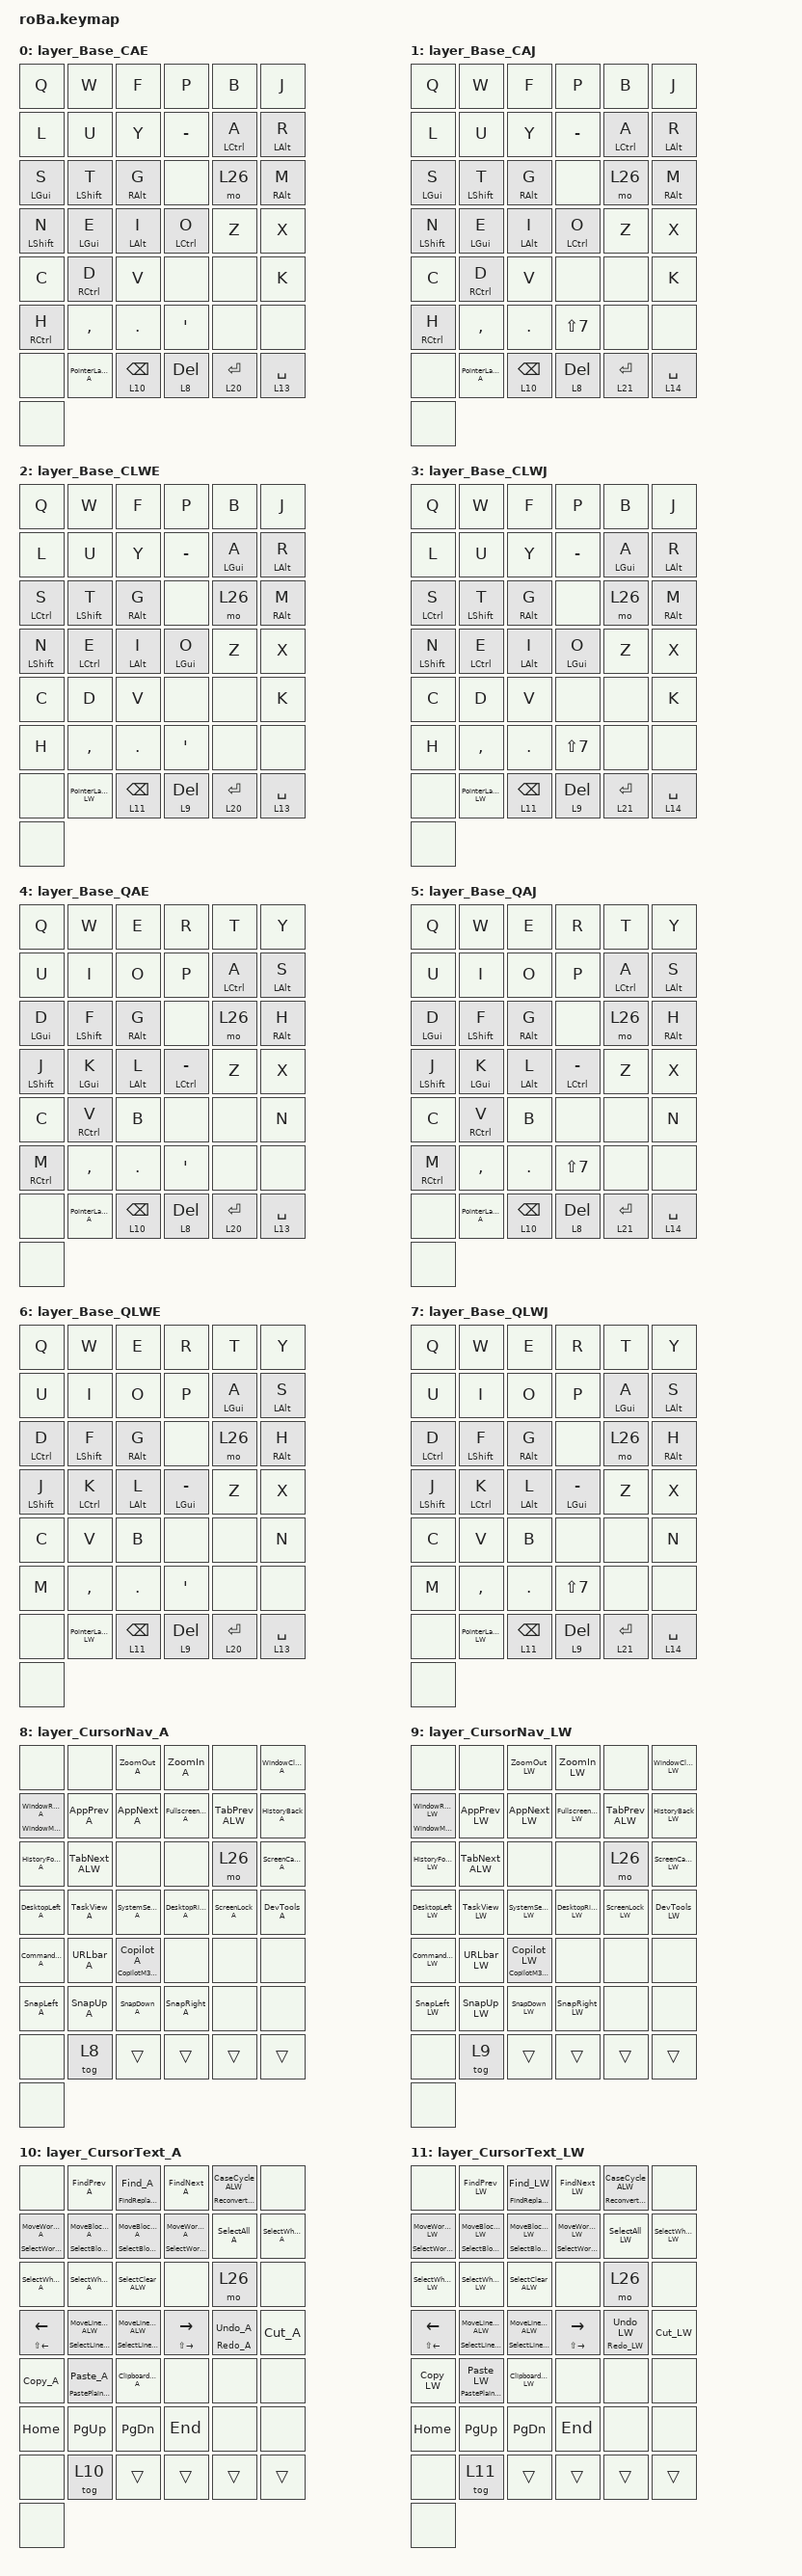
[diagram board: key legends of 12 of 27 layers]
/*
 * Copyright (c) 2020 The ZMK Contributors
 * Copyright (c) 2025 Innaworks Development Limited, trading as MoErgo
 *
 * SPDX-License-Identifier: MIT
 */


/* roBa conversion generated from 9605b8a6-7994-4d04-98d7-80160d29d007_ks35.json; based on last-known-good roBa keymap structure. */

#include <behaviors.dtsi>

/* Include all behavior includes needed */

#include <dt-bindings/zmk/outputs.h>
#include <dt-bindings/zmk/keys.h>
#include <dt-bindings/zmk/bt.h>
#include <dt-bindings/zmk/rgb.h>

#include <input/processors.dtsi>
#include <dt-bindings/zmk/input_transform.h>
#include <zephyr/dt-bindings/input/input-event-codes.h>

/* On demand includes */
#include <dt-bindings/zmk/input_transform.h>
#include <dt-bindings/zmk/pointing.h>
#include <input/processors.dtsi>

/* Helper Macros, based on https://github.com/urob/zmk-helpers/ */

#pragma once

#define ZMK_HELPER_STRINGIFY(x) #x

// Preprocessor mechanism to overload macros, cf. https://stackoverflow.com/a/27051616/6114651
#define VARGS_(_10, _9, _8, _7, _6, _5, _4, _3, _2, _1, N, ...) N
#define VARGS(...) VARGS_(__VA_ARGS__, 10, 9, 8, 7, 6, 5, 4, 3, 2, 1, 0)
#define CONCAT_(a, b) a##b
#define CONCAT(a, b) CONCAT_(a, b)

#define ZMK_BEHAVIOR_CORE_tap_dance  \
    compatible = "zmk,behavior-tap-dance"; \
    #binding-cells = <0>

#define ZMK_BEHAVIOR(name, type, ...) \
    name: name { \
        ZMK_BEHAVIOR_CORE_ ## type; \
        __VA_ARGS__ \
    };

#define ZMK_TAP_DANCE(name, ...) \
    ZMK_BEHAVIOR(name, tap_dance, __VA_ARGS__)

#define ZMK_TD_LAYER(name, layer) \
    ZMK_TAP_DANCE(name, \
        tapping-term-ms = <200>; \
        bindings = <&mo layer>, <&to layer>; \
)


/* Automatically generated roBa layer name defines */
#define LAYER_Base_CAE 0
#define LAYER_Base_CAJ 1
#define LAYER_Base_CLWE 2
#define LAYER_Base_CLWJ 3
#define LAYER_Base_QAE 4
#define LAYER_Base_QAJ 5
#define LAYER_Base_QLWE 6
#define LAYER_Base_QLWJ 7
#define LAYER_CursorNav_A 8
#define LAYER_CursorNav_LW 9
#define LAYER_CursorText_A 10
#define LAYER_CursorText_LW 11
#define LAYER_Magic 12
#define LAYER_Number_E 13
#define LAYER_Number_J 14
#define LAYER_Pointer_Default_A 15
#define LAYER_Pointer_Default_LW 16
#define LAYER_Pointer_Precision 17
#define LAYER_Pointer_Rapid 18
#define LAYER_Pointer_Travel 19
#define LAYER_Symbol_E 20
#define LAYER_Symbol_J 21
#define LAYER_TypingAutoshift_C 22
#define LAYER_TypingAutoshift_Q 23
#define LAYER_TypingFocus_C 24
#define LAYER_TypingFocus_Q 25
#define LAYER_HSCROLL 26

#define COMBO_MAX_COMBOS_PER_KEY 8


/* System behavior and macros */


/ {
    macros {
        rgb_ug_status_macro: rgb_ug_status_macro {
            label = "RGB_UG_STATUS";
            compatible = "zmk,behavior-macro";
            #binding-cells = <0>;
            bindings
                = <&rgb_ug RGB_TOG>;
        };

        SelectAll_A: SelectAll_A {
            label = "&SELECTALL_A";
            compatible = "zmk,behavior-macro";
            #binding-cells = <0>;
            bindings = <&kp LG(A)>;
        };

        SelectAll_LW: SelectAll_LW {
            label = "&SELECTALL_LW";
            compatible = "zmk,behavior-macro";
            #binding-cells = <0>;
            bindings = <&kp LC(A)>;
        };

        IME_Off_A: IME_Off_A {
            label = "&IME_OFF_A";
            compatible = "zmk,behavior-macro";
            #binding-cells = <0>;
            bindings = <&kp LANG2>;
        };

        IME_Off_LW: IME_Off_LW {
            label = "&IME_OFF_LW";
            compatible = "zmk,behavior-macro";
            #binding-cells = <0>;
            bindings = <&kp INT5>;
        };

        IME_ON_A: IME_ON_A {
            label = "&IME_ON_A";
            compatible = "zmk,behavior-macro";
            #binding-cells = <0>;
            bindings = <&kp LANG1>;
        };

        IME_ON_LW: IME_ON_LW {
            label = "&IME_ON_LW";
            compatible = "zmk,behavior-macro";
            #binding-cells = <0>;
            bindings = <&kp INT4>;
        };

    };
};



/ {
    behaviors {
        magic: magic {
            compatible = "zmk,behavior-hold-tap";
            label = "MAGIC_HOLD_TAP";
            #binding-cells = <2>;
            flavor = "tap-preferred";
            tapping-term-ms = <200>;
            bindings = <&mo>, <&rgb_ug_status_macro>;
        };
    };
};


/* Custom Defined Behaviors */


/* Automatically generated macro definitions */
/ {
    macros {

        AppNext_A: AppNext_A {
            label = "&APPNEXT_A";
            compatible = "zmk,behavior-macro";
            #binding-cells = <0>;
            bindings = <&kp LG(TAB)>;
        };

        AppNext_LW: AppNext_LW {
            label = "&APPNEXT_LW";
            compatible = "zmk,behavior-macro";
            #binding-cells = <0>;
            bindings = <&kp LA(TAB)>;
        };

        AppPrev_A: AppPrev_A {
            label = "&APPPREV_A";
            compatible = "zmk,behavior-macro";
            #binding-cells = <0>;
            bindings = <&kp LG(LS(TAB))>;
        };

        AppPrev_LW: AppPrev_LW {
            label = "&APPPREV_LW";
            compatible = "zmk,behavior-macro";
            #binding-cells = <0>;
            bindings = <&kp LA(LS(TAB))>;
        };

        // AutoShift Helper- &AS main macro is chained to &AS_HT hold tap and &AS_Shifted macro - TailorKey
        AS_Shifted_v1_TKZ: AS_Shifted_v1_TKZ {
            label = "&AS_SHIFTED_V1_TKZ";
            compatible = "zmk,behavior-macro-one-param";
            #binding-cells = <1>;
            tap-ms = <0>;
            wait-ms = <0>;
            bindings = <&macro_press>
                , <&kp LSHFT>
                , <&macro_tap>
                , <&macro_param_1to1>
                , <&kp MACRO_PLACEHOLDER>
                , <&macro_release>
                , <&kp LSHFT>;
        };

        // AutoShift (Assign &AS to a Key) - &AS main macro is chained to &AS_HT hold tap and &AS_Shifted macro - TailorKey
        AS_v1_TKZ: AS_v1_TKZ {
            label = "&AS_V1_TKZ";
            compatible = "zmk,behavior-macro-one-param";
            #binding-cells = <1>;
            tap-ms = <0>;
            wait-ms = <0>;
            bindings = <&macro_press>
                , <&macro_param_1to1>
                , <&macro_param_1to2>
                , <&HT_AutoShift MACRO_PLACEHOLDER MACRO_PLACEHOLDER>
                , <&macro_pause_for_release>
                , <&macro_release>
                , <&macro_param_1to1>
                , <&macro_param_1to2>
                , <&HT_AutoShift MACRO_PLACEHOLDER MACRO_PLACEHOLDER>;
        };

        CaseCycle_ALW: CaseCycle_ALW {
            label = "&CASECYCLE_ALW";
            compatible = "zmk,behavior-macro";
            #binding-cells = <0>;
            bindings = <&kp LS(F3)>;
        };

        ClipboardHistory_A: ClipboardHistory_A {
            label = "&CLIPBOARDHISTORY_A";
            compatible = "zmk,behavior-macro";
            #binding-cells = <0>;
            bindings = <&kp LG(SPACE)>
                , <&kp LG(N4)>;
        };

        ClipboardHistory_LW: ClipboardHistory_LW {
            label = "&CLIPBOARDHISTORY_LW";
            compatible = "zmk,behavior-macro";
            #binding-cells = <0>;
            bindings = <&kp LG(V)>;
        };

        CommandPalette_A: CommandPalette_A {
            label = "&COMMANDPALETTE_A";
            compatible = "zmk,behavior-macro";
            #binding-cells = <0>;
            bindings = <&kp LG(LS(P))>;
        };

        CommandPalette_LW: CommandPalette_LW {
            label = "&COMMANDPALETTE_LW";
            compatible = "zmk,behavior-macro";
            #binding-cells = <0>;
            bindings = <&kp LS(LC(P))>;
        };

        Copilot_A: Copilot_A {
            label = "&COPILOT_A";
            compatible = "zmk,behavior-macro";
            #binding-cells = <0>;
            bindings = <&kp LA(SPACE)>;
        };

        Copilot_LW: Copilot_LW {
            label = "&COPILOT_LW";
            compatible = "zmk,behavior-macro";
            #binding-cells = <0>;
            bindings = <&kp LG(C)>;
        };

        CopilotM365_A: CopilotM365_A {
            label = "&COPILOTM365_A";
            compatible = "zmk,behavior-macro";
            #binding-cells = <0>;
            bindings = <&kp LG(LC(I))>;
        };

        CopilotM365_LW: CopilotM365_LW {
            label = "&COPILOTM365_LW";
            compatible = "zmk,behavior-macro";
            #binding-cells = <0>;
            bindings = <&kp LA(C)>;
        };

        Copy_A: Copy_A {
            label = "&COPY_A";
            compatible = "zmk,behavior-macro";
            #binding-cells = <0>;
            bindings = <&kp LG(C)>;
        };

        Copy_LW: Copy_LW {
            label = "&COPY_LW";
            compatible = "zmk,behavior-macro";
            #binding-cells = <0>;
            bindings = <&kp LC(C)>;
        };

        Cut_A: Cut_A {
            label = "&CUT_A";
            compatible = "zmk,behavior-macro";
            #binding-cells = <0>;
            bindings = <&kp LG(X)>;
        };

        Cut_LW: Cut_LW {
            label = "&CUT_LW";
            compatible = "zmk,behavior-macro";
            #binding-cells = <0>;
            bindings = <&kp LC(X)>;
        };

        DesktopLeft_A: DesktopLeft_A {
            label = "&DESKTOPLEFT_A";
            compatible = "zmk,behavior-macro";
            #binding-cells = <0>;
            bindings = <&kp LC(LEFT)>;
        };

        DesktopLeft_LW: DesktopLeft_LW {
            label = "&DESKTOPLEFT_LW";
            compatible = "zmk,behavior-macro";
            #binding-cells = <0>;
            bindings = <&kp LC(LG(LEFT))>;
        };

        DesktopRight_A: DesktopRight_A {
            label = "&DESKTOPRIGHT_A";
            compatible = "zmk,behavior-macro";
            #binding-cells = <0>;
            bindings = <&kp LC(RIGHT)>;
        };

        DesktopRight_LW: DesktopRight_LW {
            label = "&DESKTOPRIGHT_LW";
            compatible = "zmk,behavior-macro";
            #binding-cells = <0>;
            bindings = <&kp LC(LG(RIGHT))>;
        };

        DevTools_A: DevTools_A {
            label = "&DEVTOOLS_A";
            compatible = "zmk,behavior-macro";
            #binding-cells = <0>;
            bindings = <&kp LG(LA(I))>;
        };

        DevTools_LW: DevTools_LW {
            label = "&DEVTOOLS_LW";
            compatible = "zmk,behavior-macro";
            #binding-cells = <0>;
            bindings = <&kp LS(LC(I))>;
        };

        DocEnd_A: DocEnd_A {
            label = "&DOCEND_A";
            compatible = "zmk,behavior-macro";
            #binding-cells = <0>;
            bindings = <&kp LG(DOWN)>;
        };

        DocEnd_LW: DocEnd_LW {
            label = "&DOCEND_LW";
            compatible = "zmk,behavior-macro";
            #binding-cells = <0>;
            bindings = <&kp LC(END)>;
        };

        DocStart_A: DocStart_A {
            label = "&DOCSTART_A";
            compatible = "zmk,behavior-macro";
            #binding-cells = <0>;
            bindings = <&kp LG(UP)>;
        };

        DocStart_LW: DocStart_LW {
            label = "&DOCSTART_LW";
            compatible = "zmk,behavior-macro";
            #binding-cells = <0>;
            bindings = <&kp LC(HOME)>;
        };

        EmojiPicker_A: EmojiPicker_A {
            label = "&EMOJIPICKER_A";
            compatible = "zmk,behavior-macro";
            #binding-cells = <0>;
            bindings = <&kp LG(LC(SPACE))>;
        };

        EmojiPicker_LW: EmojiPicker_LW {
            label = "&EMOJIPICKER_LW";
            compatible = "zmk,behavior-macro";
            #binding-cells = <0>;
            bindings = <&kp LG(DOT)>;
        };

        Find_A: Find_A {
            label = "&FIND_A";
            compatible = "zmk,behavior-macro";
            #binding-cells = <0>;
            bindings = <&kp LG(F)>;
        };

        Find_LW: Find_LW {
            label = "&FIND_LW";
            compatible = "zmk,behavior-macro";
            #binding-cells = <0>;
            bindings = <&kp LC(F)>;
        };

        FindNext_A: FindNext_A {
            label = "&FINDNEXT_A";
            compatible = "zmk,behavior-macro";
            #binding-cells = <0>;
            bindings = <&kp LG(G)>;
        };

        FindNext_LW: FindNext_LW {
            label = "&FINDNEXT_LW";
            compatible = "zmk,behavior-macro";
            #binding-cells = <0>;
            bindings = <&kp F3>;
        };

        FindPrev_A: FindPrev_A {
            label = "&FINDPREV_A";
            compatible = "zmk,behavior-macro";
            #binding-cells = <0>;
            bindings = <&kp LS(LG(G))>;
        };

        FindPrev_LW: FindPrev_LW {
            label = "&FINDPREV_LW";
            compatible = "zmk,behavior-macro";
            #binding-cells = <0>;
            bindings = <&kp LS(F3)>;
        };

        FindReplace_A: FindReplace_A {
            label = "&FINDREPLACE_A";
            compatible = "zmk,behavior-macro";
            #binding-cells = <0>;
            bindings = <&kp LG(LA(F))>;
        };

        FindReplace_LW: FindReplace_LW {
            label = "&FINDREPLACE_LW";
            compatible = "zmk,behavior-macro";
            #binding-cells = <0>;
            bindings = <&kp LC(H)>;
        };

        FullscreenToggle_A: FullscreenToggle_A {
            label = "&FULLSCREENTOGGLE_A";
            compatible = "zmk,behavior-macro";
            #binding-cells = <0>;
            bindings = <&kp LG(LC(F))>;
        };

        FullscreenToggle_LW: FullscreenToggle_LW {
            label = "&FULLSCREENTOGGLE_LW";
            compatible = "zmk,behavior-macro";
            #binding-cells = <0>;
            bindings = <&kp F11>;
        };

        HistoryBack_A: HistoryBack_A {
            label = "&HISTORYBACK_A";
            compatible = "zmk,behavior-macro";
            #binding-cells = <0>;
            bindings = <&kp LG(LEFT)>;
        };

        HistoryBack_LW: HistoryBack_LW {
            label = "&HISTORYBACK_LW";
            compatible = "zmk,behavior-macro";
            #binding-cells = <0>;
            bindings = <&kp LA(LEFT)>;
        };

        HistoryForward_A: HistoryForward_A {
            label = "&HISTORYFORWARD_A";
            compatible = "zmk,behavior-macro";
            #binding-cells = <0>;
            bindings = <&kp LG(RIGHT)>;
        };

        HistoryForward_LW: HistoryForward_LW {
            label = "&HISTORYFORWARD_LW";
            compatible = "zmk,behavior-macro";
            #binding-cells = <0>;
            bindings = <&kp LA(RIGHT)>;
        };

        InputSwitch_ALW: InputSwitch_ALW {
            label = "&INPUTSWITCH_ALW";
            compatible = "zmk,behavior-macro";
            #binding-cells = <0>;
            bindings = <&kp LC(SPACE)>;
        };

        InputSwitch_LW: InputSwitch_LW {
            label = "&INPUTSWITCH_LW";
            compatible = "zmk,behavior-macro";
            #binding-cells = <0>;
            bindings = <&kp LA(LSHFT)>;
        };

        // mod_tab_switcher_chord -  TailorKey
        mod_tab_chord_v2_TKZ: mod_tab_chord_v2_TKZ {
            label = "&MOD_TAB_CHORD_V2_TKZ";
            compatible = "zmk,behavior-macro-two-param";
            #binding-cells = <2>;
            tap-ms = <0>;
            wait-ms = <0>;
            bindings = <&macro_press>
                , <&macro_param_2to1>
                , <&mo MACRO_PLACEHOLDER>
                , <&macro_press>
                , <&macro_param_1to1>
                , <&mod_tab_v2_TKZ MACRO_PLACEHOLDER>
                , <&macro_pause_for_release>
                , <&macro_release>
                , <&macro_param_1to1>
                , <&mod_tab_v2_TKZ MACRO_PLACEHOLDER>
                , <&macro_release>
                , <&macro_param_2to1>
                , <&mo MACRO_PLACEHOLDER>;
        };

        // mod_tab_switcher - TailorKey
        //
        //
        mod_tab_v2_TKZ: mod_tab_v2_TKZ {
            label = "&MOD_TAB_V2_TKZ";
            compatible = "zmk,behavior-macro-one-param";
            #binding-cells = <1>;
            tap-ms = <0>;
            wait-ms = <0>;
            bindings = <&macro_press>
                , <&macro_param_1to1>
                , <&kp MACRO_PLACEHOLDER>
                , <&macro_tap>
                , <&kp TAB>
                , <&macro_pause_for_release>
                , <&macro_release>
                , <&macro_param_1to1>
                , <&kp MACRO_PLACEHOLDER>;
        };

        MoveBlockNext_A: MoveBlockNext_A {
            label = "&MOVEBLOCKNEXT_A";
            compatible = "zmk,behavior-macro";
            #binding-cells = <0>;
            bindings = <&kp LA(DOWN)>;
        };

        MoveBlockNext_LW: MoveBlockNext_LW {
            label = "&MOVEBLOCKNEXT_LW";
            compatible = "zmk,behavior-macro";
            #binding-cells = <0>;
            bindings = <&kp LC(DOWN)>;
        };

        MoveBlockPrev_A: MoveBlockPrev_A {
            label = "&MOVEBLOCKPREV_A";
            compatible = "zmk,behavior-macro";
            #binding-cells = <0>;
            bindings = <&kp LA(UP)>;
        };

        MoveBlockPrev_LW: MoveBlockPrev_LW {
            label = "&MOVEBLOCKPREV_LW";
            compatible = "zmk,behavior-macro";
            #binding-cells = <0>;
            bindings = <&kp LC(UP)>;
        };

        MoveWordNext_A: MoveWordNext_A {
            label = "&MOVEWORDNEXT_A";
            compatible = "zmk,behavior-macro";
            #binding-cells = <0>;
            bindings = <&kp LA(RIGHT)>;
        };

        MoveWordNext_LW: MoveWordNext_LW {
            label = "&MOVEWORDNEXT_LW";
            compatible = "zmk,behavior-macro";
            #binding-cells = <0>;
            bindings = <&kp LC(RIGHT)>;
        };

        MoveWordPrev_A: MoveWordPrev_A {
            label = "&MOVEWORDPREV_A";
            compatible = "zmk,behavior-macro";
            #binding-cells = <0>;
            bindings = <&kp LA(LEFT)>;
        };

        MoveWordPrev_LW: MoveWordPrev_LW {
            label = "&MOVEWORDPREV_LW";
            compatible = "zmk,behavior-macro";
            #binding-cells = <0>;
            bindings = <&kp LC(LEFT)>;
        };

        Paste_A: Paste_A {
            label = "&PASTE_A";
            compatible = "zmk,behavior-macro";
            #binding-cells = <0>;
            bindings = <&kp LG(V)>;
        };

        Paste_LW: Paste_LW {
            label = "&PASTE_LW";
            compatible = "zmk,behavior-macro";
            #binding-cells = <0>;
            bindings = <&kp LC(V)>;
        };

        PastePlain_A: PastePlain_A {
            label = "&PASTEPLAIN_A";
            compatible = "zmk,behavior-macro";
            #binding-cells = <0>;
            bindings = <&kp LS(LA(LG(V)))>;
        };

        PastePlain_LW: PastePlain_LW {
            label = "&PASTEPLAIN_LW";
            compatible = "zmk,behavior-macro";
            #binding-cells = <0>;
            bindings = <&kp LS(LC(V))>;
        };

        Reconvert_A: Reconvert_A {
            label = "&RECONVERT_A";
            compatible = "zmk,behavior-macro";
            #binding-cells = <0>;
            bindings = <&kp LS(LC(R))>;
        };

        Reconvert_LW: Reconvert_LW {
            label = "&RECONVERT_LW";
            compatible = "zmk,behavior-macro";
            #binding-cells = <0>;
            bindings = <&kp LC(BSPC)>;
        };

        Redo_A: Redo_A {
            label = "&REDO_A";
            compatible = "zmk,behavior-macro";
            #binding-cells = <0>;
            bindings = <&kp LG(LS(Z))>;
        };

        Redo_LW: Redo_LW {
            label = "&REDO_LW";
            compatible = "zmk,behavior-macro";
            #binding-cells = <0>;
            bindings = <&kp LC(Y)>;
        };

        ScreenCapture_A: ScreenCapture_A {
            label = "&SCREENCAPTURE_A";
            compatible = "zmk,behavior-macro";
            #binding-cells = <0>;
            bindings = <&kp LG(LS(N5))>;
        };

        ScreenCapture_LW: ScreenCapture_LW {
            label = "&SCREENCAPTURE_LW";
            compatible = "zmk,behavior-macro";
            #binding-cells = <0>;
            bindings = <&kp LG(LS(S))>;
        };

        ScreenLock_A: ScreenLock_A {
            label = "&SCREENLOCK_A";
            compatible = "zmk,behavior-macro";
            #binding-cells = <0>;
            bindings = <&kp LC(LG(Q))>;
        };

        ScreenLock_LW: ScreenLock_LW {
            label = "&SCREENLOCK_LW";
            compatible = "zmk,behavior-macro";
            #binding-cells = <0>;
            bindings = <&kp LG(L)>;
        };

        SelectBlockNext_A: SelectBlockNext_A {
            label = "&SELECTBLOCKNEXT_A";
            compatible = "zmk,behavior-macro";
            #binding-cells = <0>;
            bindings = <&kp LA(LS(DOWN))>;
        };

        SelectBlockNext_LW: SelectBlockNext_LW {
            label = "&SELECTBLOCKNEXT_LW";
            compatible = "zmk,behavior-macro";
            #binding-cells = <0>;
            bindings = <&kp LS(LC(DOWN))>;
        };

        SelectBlockPrev_A: SelectBlockPrev_A {
            label = "&SELECTBLOCKPREV_A";
            compatible = "zmk,behavior-macro";
            #binding-cells = <0>;
            bindings = <&kp LA(LS(UP))>;
        };

        SelectBlockPrev_LW: SelectBlockPrev_LW {
            label = "&SELECTBLOCKPREV_LW";
            compatible = "zmk,behavior-macro";
            #binding-cells = <0>;
            bindings = <&kp LS(LC(UP))>;
        };

        // Cursor Layer - Select None (seq) - TailorKey
        SelectClear_ALW: SelectClear_ALW {
            label = "&SELECTCLEAR_ALW";
            compatible = "zmk,behavior-macro";
            #binding-cells = <0>;
            tap-ms = <1>;
            wait-ms = <1>;
            bindings = <&kp DOWN>
                , <&kp UP>
                , <&kp RIGHT>
                , <&kp LEFT>;
        };

        // Cursor Layer - Extent Line (seq) - TailorKey
        SelectLineNext_A: SelectLineNext_A {
            label = "&SELECTLINENEXT_A";
            compatible = "zmk,behavior-macro";
            #binding-cells = <0>;
            tap-ms = <1>;
            wait-ms = <1>;
            bindings = <&kp LG(LS(RIGHT))>;
        };

        // Cursor Layer - Extent Line (seq) - TailorKey
        SelectLineNext_LW: SelectLineNext_LW {
            label = "&SELECTLINENEXT_LW";
            compatible = "zmk,behavior-macro";
            #binding-cells = <0>;
            tap-ms = <1>;
            wait-ms = <1>;
            bindings = <&kp LS(END)>;
        };

        SelectLinePrev_A: SelectLinePrev_A {
            label = "&SELECTLINEPREV_A";
            compatible = "zmk,behavior-macro";
            #binding-cells = <0>;
            bindings = <&kp LS(LG(LEFT))>;
        };

        SelectLinePrev_LW: SelectLinePrev_LW {
            label = "&SELECTLINEPREV_LW";
            compatible = "zmk,behavior-macro";
            #binding-cells = <0>;
            bindings = <&kp LS(HOME)>;
        };

        SelectWholeBlock_A: SelectWholeBlock_A {
            label = "&SELECTWHOLEBLOCK_A";
            compatible = "zmk,behavior-macro";
            #binding-cells = <0>;
            bindings = <&kp LC(A)>
                , <&kp LA(LS(DOWN))>;
        };

        SelectWholeBlock_LW: SelectWholeBlock_LW {
            label = "&SELECTWHOLEBLOCK_LW";
            compatible = "zmk,behavior-macro";
            #binding-cells = <0>;
            bindings = <&kp LC(UP)>
                , <&kp LS(LC(DOWN))>;
        };

        // Cursor Layer macos - Select Line (seq) - TailorKey
        SelectWholeLine_A: SelectWholeLine_A {
            label = "&SELECTWHOLELINE_A";
            compatible = "zmk,behavior-macro";
            #binding-cells = <0>;
            tap-ms = <1>;
            wait-ms = <1>;
            bindings = <&kp LG(LEFT)>
                , <&kp LG(LS(RIGHT))>;
        };

        // Cursor Layer - Select Line (seq) - TailorKey
        SelectWholeLine_LW: SelectWholeLine_LW {
            label = "&SELECTWHOLELINE_LW";
            compatible = "zmk,behavior-macro";
            #binding-cells = <0>;
            tap-ms = <1>;
            wait-ms = <1>;
            bindings = <&kp HOME>
                , <&kp LS(END)>;
        };

        // Cursor Layer - Select Word (seq) - TailorKey
        SelectWholeWord_A: SelectWholeWord_A {
            label = "&SELECTWHOLEWORD_A";
            compatible = "zmk,behavior-macro";
            #binding-cells = <0>;
            tap-ms = <1>;
            wait-ms = <1>;
            bindings = <&kp LA(LEFT)>
                , <&kp LA(LS(RIGHT))>;
        };

        // Cursor Layer - Select Word (seq) - TailorKey
        SelectWholeWord_LW: SelectWholeWord_LW {
            label = "&SELECTWHOLEWORD_LW";
            compatible = "zmk,behavior-macro";
            #binding-cells = <0>;
            tap-ms = <1>;
            wait-ms = <1>;
            bindings = <&kp LC(LEFT)>
                , <&kp LC(LS(RIGHT))>;
        };

        // Cursor Layer - Extend Word (seq) - TailorKey
        SelectWordNext_A: SelectWordNext_A {
            label = "&SELECTWORDNEXT_A";
            compatible = "zmk,behavior-macro";
            #binding-cells = <0>;
            tap-ms = <1>;
            wait-ms = <1>;
            bindings = <&kp LA(LS(RIGHT))>;
        };

        // Cursor Layer - Extend Word (seq) - TailorKey
        SelectWordNext_LW: SelectWordNext_LW {
            label = "&SELECTWORDNEXT_LW";
            compatible = "zmk,behavior-macro";
            #binding-cells = <0>;
            tap-ms = <1>;
            wait-ms = <1>;
            bindings = <&kp LC(LS(RIGHT))>;
        };

        SelectWordPrev_A: SelectWordPrev_A {
            label = "&SELECTWORDPREV_A";
            compatible = "zmk,behavior-macro";
            #binding-cells = <0>;
            bindings = <&kp LA(LS(LEFT))>;
        };

        SelectWordPrev_LW: SelectWordPrev_LW {
            label = "&SELECTWORDPREV_LW";
            compatible = "zmk,behavior-macro";
            #binding-cells = <0>;
            bindings = <&kp LS(LC(LEFT))>;
        };

        SnapDown_A: SnapDown_A {
            label = "&SNAPDOWN_A";
            compatible = "zmk,behavior-macro";
            #binding-cells = <0>;
            bindings = <&kp LC(LS(RC(DOWN)))>;
        };

        SnapDown_LW: SnapDown_LW {
            label = "&SNAPDOWN_LW";
            compatible = "zmk,behavior-macro";
            #binding-cells = <0>;
            bindings = <&kp LA(LG(DOWN))>;
        };

        SnapLeft_A: SnapLeft_A {
            label = "&SNAPLEFT_A";
            compatible = "zmk,behavior-macro";
            #binding-cells = <0>;
            bindings = <&kp LC(LS(RC(LEFT)))>;
        };

        SnapLeft_LW: SnapLeft_LW {
            label = "&SNAPLEFT_LW";
            compatible = "zmk,behavior-macro";
            #binding-cells = <0>;
            bindings = <&kp LG(LEFT)>;
        };

        SnapRight_A: SnapRight_A {
            label = "&SNAPRIGHT_A";
            compatible = "zmk,behavior-macro";
            #binding-cells = <0>;
            bindings = <&kp LS(LC(RC(RIGHT)))>;
        };

        SnapRight_LW: SnapRight_LW {
            label = "&SNAPRIGHT_LW";
            compatible = "zmk,behavior-macro";
            #binding-cells = <0>;
            bindings = <&kp LG(RIGHT)>;
        };

        SnapUp_A: SnapUp_A {
            label = "&SNAPUP_A";
            compatible = "zmk,behavior-macro";
            #binding-cells = <0>;
            bindings = <&kp LS(LC(RC(UP)))>;
        };

        SnapUp_LW: SnapUp_LW {
            label = "&SNAPUP_LW";
            compatible = "zmk,behavior-macro";
            #binding-cells = <0>;
            bindings = <&kp LG(LA(UP))>;
        };

        SystemSearch_A: SystemSearch_A {
            label = "&SYSTEMSEARCH_A";
            compatible = "zmk,behavior-macro";
            #binding-cells = <0>;
            bindings = <&kp LG(SPACE)>;
        };

        SystemSearch_LW: SystemSearch_LW {
            label = "&SYSTEMSEARCH_LW";
            compatible = "zmk,behavior-macro";
            #binding-cells = <0>;
            bindings = <&kp LG(S)>;
        };

        TabNext_ALW: TabNext_ALW {
            label = "&TABNEXT_ALW";
            compatible = "zmk,behavior-macro";
            #binding-cells = <0>;
            bindings = <&kp LC(TAB)>;
        };

        TabPrev_ALW: TabPrev_ALW {
            label = "&TABPREV_ALW";
            compatible = "zmk,behavior-macro";
            #binding-cells = <0>;
            bindings = <&kp LC(LS(TAB))>;
        };

        TaskView_A: TaskView_A {
            label = "&TASKVIEW_A";
            compatible = "zmk,behavior-macro";
            #binding-cells = <0>;
            bindings = <&kp LC(UP)>;
        };

        TaskView_LW: TaskView_LW {
            label = "&TASKVIEW_LW";
            compatible = "zmk,behavior-macro";
            #binding-cells = <0>;
            bindings = <&kp LG(TAB)>;
        };

        Undo_A: Undo_A {
            label = "&UNDO_A";
            compatible = "zmk,behavior-macro";
            #binding-cells = <0>;
            bindings = <&kp LG(Z)>;
        };

        Undo_LW: Undo_LW {
            label = "&UNDO_LW";
            compatible = "zmk,behavior-macro";
            #binding-cells = <0>;
            bindings = <&kp LC(Z)>;
        };

        URLbar_A: URLbar_A {
            label = "&URLBAR_A";
            compatible = "zmk,behavior-macro";
            #binding-cells = <0>;
            bindings = <&kp LG(L)>;
        };

        URLbar_LW: URLbar_LW {
            label = "&URLBAR_LW";
            compatible = "zmk,behavior-macro";
            #binding-cells = <0>;
            bindings = <&kp LC(L)>;
        };

        WindowClose_A: WindowClose_A {
            label = "&WINDOWCLOSE_A";
            compatible = "zmk,behavior-macro";
            #binding-cells = <0>;
            bindings = <&kp LG(W)>;
        };

        WindowClose_LW: WindowClose_LW {
            label = "&WINDOWCLOSE_LW";
            compatible = "zmk,behavior-macro";
            #binding-cells = <0>;
            bindings = <&kp LA(F4)>;
        };

        WindowMaximize_A: WindowMaximize_A {
            label = "&WINDOWMAXIMIZE_A";
            compatible = "zmk,behavior-macro";
            #binding-cells = <0>;
            bindings = <&kp LC(RC(F))>;
        };

        WindowMaximize_LW: WindowMaximize_LW {
            label = "&WINDOWMAXIMIZE_LW";
            compatible = "zmk,behavior-macro";
            #binding-cells = <0>;
            bindings = <&kp LS(LG(RET))>;
        };

        WindowRestore_A: WindowRestore_A {
            label = "&WINDOWRESTORE_A";
            compatible = "zmk,behavior-macro";
            #binding-cells = <0>;
            bindings = <&kp LC(RC(R))>;
        };

        WindowRestore_LW: WindowRestore_LW {
            label = "&WINDOWRESTORE_LW";
            compatible = "zmk,behavior-macro";
            #binding-cells = <0>;
            bindings = <&kp LS(LG(DOWN))>;
        };

        ZoomIn_A: ZoomIn_A {
            label = "&ZOOMIN_A";
            compatible = "zmk,behavior-macro";
            #binding-cells = <0>;
            bindings = <&kp LG(KP_PLUS)>;
        };

        ZoomIn_LW: ZoomIn_LW {
            label = "&ZOOMIN_LW";
            compatible = "zmk,behavior-macro";
            #binding-cells = <0>;
            bindings = <&kp LC(KP_PLUS)>;
        };

        ZoomOut_A: ZoomOut_A {
            label = "&ZOOMOUT_A";
            compatible = "zmk,behavior-macro";
            #binding-cells = <0>;
            bindings = <&kp LG(KP_MINUS)>;
        };

        ZoomOut_LW: ZoomOut_LW {
            label = "&ZOOMOUT_LW";
            compatible = "zmk,behavior-macro";
            #binding-cells = <0>;
            bindings = <&kp LC(KP_MINUS)>;
        };

        ZoomReset_A: ZoomReset_A {
            label = "&ZOOMRESET_A";
            compatible = "zmk,behavior-macro";
            #binding-cells = <0>;
            bindings = <&kp LG(N0)>;
        };

        ZoomReset_LW: ZoomReset_LW {
            label = "&ZOOMRESET_LW";
            compatible = "zmk,behavior-macro";
            #binding-cells = <0>;
            bindings = <&kp LC(N0)>;
        };
    };
};

/* Automatically generated behavior definitions */
/ {
    behaviors {


        HRM_LHC1R3: HRM_LHC1R3 {
            compatible = "zmk,behavior-hold-tap";
            #binding-cells = <2>;
            tapping-term-ms = <280>;
            bindings = <&kp>, <&kp>;
            flavor = "tap-preferred";
            quick-tap-ms = <300>;
            require-prior-idle-ms = <150>;
            hold-trigger-key-positions = <5 6 7 8 9 16 17 18 19 20 21 28 29 30 31 32 33 42 37 38 39 40 41>;
            hold-trigger-on-release;
        };

        // Homerow Mod for the left index finger - TailorKey.
        // For advanced tuning of HRM values, see: https://docs.google.com/spreadsheets/d/1ESgObQelyz4lnKlfwLYsmofLJulOMK5RdGBsopLe2o8
        HRM_LHC2R3: HRM_LHC2R3 {
            compatible = "zmk,behavior-hold-tap";
            #binding-cells = <2>;
            tapping-term-ms = <190>;
            bindings = <&kp>, <&kp>;
            flavor = "tap-preferred";
            quick-tap-ms = <300>;
            require-prior-idle-ms = <100>;
            hold-trigger-key-positions = <5 6 7 8 9 16 17 18 19 20 21 28 29 30 31 32 33 42 37 38 39 40 41>;
            hold-trigger-on-release;
        };

        HRM_LHC2R4: HRM_LHC2R4 {
            compatible = "zmk,behavior-hold-tap";
            #binding-cells = <2>;
            tapping-term-ms = <280>;
            bindings = <&kp>, <&kp>;
            flavor = "tap-preferred";
            quick-tap-ms = <300>;
            require-prior-idle-ms = <150>;
            hold-trigger-key-positions = <5 6 7 8 9 16 17 18 19 20 21 28 29 30 31 32 33 42 37 38 39 40 41>;
            hold-trigger-on-release;
        };

        // Homerow Mod for the left middle finger - TailorKey
        HRM_LHC3R3: HRM_LHC3R3 {
            compatible = "zmk,behavior-hold-tap";
            #binding-cells = <2>;
            tapping-term-ms = <210>;
            bindings = <&kp>, <&kp>;
            flavor = "tap-preferred";
            quick-tap-ms = <300>;
            require-prior-idle-ms = <150>;
            hold-trigger-key-positions = <5 6 7 8 9 16 17 18 19 20 21 28 29 30 31 32 33 42 37 38 39 40 41>;
            hold-trigger-on-release;
        };

        // Homerow Mod for the left ring finger 1 - TailorKey
        HRM_LHC4R3: HRM_LHC4R3 {
            compatible = "zmk,behavior-hold-tap";
            #binding-cells = <2>;
            tapping-term-ms = <240>;
            bindings = <&kp>, <&kp>;
            flavor = "tap-preferred";
            quick-tap-ms = <300>;
            require-prior-idle-ms = <150>;
            hold-trigger-key-positions = <5 6 7 8 9 16 17 18 19 20 21 28 29 30 31 32 33 42 37 38 39 40 41>;
            hold-trigger-on-release;
        };

        // Homerow Mod for the left pinky - TailorKey
        HRM_LHC5R3: HRM_LHC5R3 {
            compatible = "zmk,behavior-hold-tap";
            #binding-cells = <2>;
            tapping-term-ms = <280>;
            bindings = <&kp>, <&kp>;
            flavor = "tap-preferred";
            quick-tap-ms = <300>;
            require-prior-idle-ms = <150>;
            hold-trigger-key-positions = <5 6 7 8 9 16 17 18 19 20 21 28 29 30 31 32 33 42 37 38 39 40 41>;
            hold-trigger-on-release;
        };

        HRM_RHC1R3: HRM_RHC1R3 {
            compatible = "zmk,behavior-hold-tap";
            #binding-cells = <2>;
            tapping-term-ms = <280>;
            bindings = <&kp>, <&kp>;
            flavor = "tap-preferred";
            quick-tap-ms = <300>;
            require-prior-idle-ms = <150>;
            hold-trigger-key-positions = <0 1 2 3 4 10 11 12 13 14 15 22 23 24 25 26 27 34 35 36 37 38 39 40 41>;
            hold-trigger-on-release;
        };

        // Homerow Mod for the right index finger - TailorKey
        HRM_RHC2R3: HRM_RHC2R3 {
            compatible = "zmk,behavior-hold-tap";
            #binding-cells = <2>;
            tapping-term-ms = <190>;
            bindings = <&kp>, <&kp>;
            flavor = "tap-preferred";
            quick-tap-ms = <300>;
            require-prior-idle-ms = <100>;
            hold-trigger-key-positions = <0 1 2 3 4 10 11 12 13 14 15 22 23 24 25 26 27 34 35 36 37 38 39 40 41>;
            hold-trigger-on-release;
        };

        HRM_RHC2R4: HRM_RHC2R4 {
            compatible = "zmk,behavior-hold-tap";
            #binding-cells = <2>;
            tapping-term-ms = <280>;
            bindings = <&kp>, <&kp>;
            flavor = "tap-preferred";
            quick-tap-ms = <300>;
            require-prior-idle-ms = <150>;
            hold-trigger-key-positions = <0 1 2 3 4 10 11 12 13 14 15 22 23 24 25 26 27 34 35 36 37 38 39 40 41>;
            hold-trigger-on-release;
        };

        // Homerow Mod for the right middle finger - TailorKey
        HRM_RHC3R3: HRM_RHC3R3 {
            compatible = "zmk,behavior-hold-tap";
            #binding-cells = <2>;
            tapping-term-ms = <210>;
            bindings = <&kp>, <&kp>;
            flavor = "tap-preferred";
            quick-tap-ms = <300>;
            require-prior-idle-ms = <150>;
            hold-trigger-key-positions = <0 1 2 3 4 10 11 12 13 14 15 22 23 24 25 26 27 34 35 36 37 38 39 40 41>;
            hold-trigger-on-release;
        };

        // Homerow Mod for the right ring 1 - TailorKey
        //
        HRM_RHC4R3: HRM_RHC4R3 {
            compatible = "zmk,behavior-hold-tap";
            #binding-cells = <2>;
            tapping-term-ms = <240>;
            bindings = <&kp>, <&kp>;
            flavor = "tap-preferred";
            quick-tap-ms = <300>;
            require-prior-idle-ms = <150>;
            hold-trigger-key-positions = <0 1 2 3 4 10 11 12 13 14 15 22 23 24 25 26 27 34 35 36 37 38 39 40 41>;
            hold-trigger-on-release;
        };

        // Homerow Mod for the right pinky - TailorKey
        HRM_RHC5R3: HRM_RHC5R3 {
            compatible = "zmk,behavior-hold-tap";
            #binding-cells = <2>;
            tapping-term-ms = <280>;
            bindings = <&kp>, <&kp>;
            flavor = "tap-preferred";
            quick-tap-ms = <300>;
            require-prior-idle-ms = <150>;
            hold-trigger-key-positions = <0 1 2 3 4 10 11 12 13 14 15 22 23 24 25 26 27 34 35 36 37 38 39 40 41>;
            hold-trigger-on-release;
        };

        // AutoShift Helper - &AS main macro is chained to &AS_HT hold tap and &AS_Shifted macro. For faster typists, it is recommended to decrease the tapping-term-ms value. A suggested value is 135 ms.
        // More: https://github.com/nickcoutsos/keymap-editor/wiki/Autoshift-using-ZMK-behaviors
        HT_AutoShift: HT_AutoShift {
            compatible = "zmk,behavior-hold-tap";
            #binding-cells = <2>;
            tapping-term-ms = <190>;
            bindings = <&AS_Shifted_v1_TKZ>, <&kp>;
            flavor = "tap-preferred";
        };

        HT_CapsWord_Shift: HT_CapsWord_Shift {
            compatible = "zmk,behavior-hold-tap";
            #binding-cells = <2>;
            tapping-term-ms = <200>;
            flavor = "tap-preferred";
            bindings = <&kp>, <&caps_word>;
        };

        HT_CaseCycle_Reconvert_A: HT_CaseCycle_Reconvert_A {
            compatible = "zmk,behavior-hold-tap";
            #binding-cells = <2>;
            tapping-term-ms = <200>;
            bindings = <&Reconvert_A>, <&CaseCycle_ALW>;
            flavor = "tap-preferred";
        };

        HT_CaseCycle_Reconvert_LW: HT_CaseCycle_Reconvert_LW {
            compatible = "zmk,behavior-hold-tap";
            #binding-cells = <2>;
            tapping-term-ms = <200>;
            bindings = <&Reconvert_LW>, <&CaseCycle_ALW>;
            flavor = "tap-preferred";
        };

        HT_Copilot_A: HT_Copilot_A {
            compatible = "zmk,behavior-hold-tap";
            #binding-cells = <2>;
            tapping-term-ms = <200>;
            bindings = <&CopilotM365_A>, <&Copilot_A>;
            flavor = "tap-preferred";
        };

        HT_Copilot_LW: HT_Copilot_LW {
            compatible = "zmk,behavior-hold-tap";
            #binding-cells = <2>;
            tapping-term-ms = <200>;
            bindings = <&CopilotM365_LW>, <&Copilot_LW>;
            flavor = "tap-preferred";
        };

        HT_Copy_ClipboardHistory_A: HT_Copy_ClipboardHistory_A {
            compatible = "zmk,behavior-hold-tap";
            #binding-cells = <2>;
            tapping-term-ms = <200>;
            bindings = <&ClipboardHistory_A>, <&Copy_A>;
            flavor = "tap-preferred";
        };

        HT_Copy_ClipboardHistory_LW: HT_Copy_ClipboardHistory_LW {
            compatible = "zmk,behavior-hold-tap";
            #binding-cells = <2>;
            tapping-term-ms = <200>;
            bindings = <&ClipboardHistory_LW>, <&Copy_LW>;
            flavor = "tap-preferred";
        };

        HT_Find_Replace_A: HT_Find_Replace_A {
            compatible = "zmk,behavior-hold-tap";
            #binding-cells = <2>;
            tapping-term-ms = <200>;
            bindings = <&FindReplace_A>, <&Find_A>;
            flavor = "tap-preferred";
        };

        HT_Find_Replace_LW: HT_Find_Replace_LW {
            compatible = "zmk,behavior-hold-tap";
            #binding-cells = <2>;
            tapping-term-ms = <200>;
            bindings = <&FindReplace_LW>, <&Find_LW>;
            flavor = "tap-preferred";
        };

        HT_InputSwitch_EmojiPicker_A: HT_InputSwitch_EmojiPicker_A {
            compatible = "zmk,behavior-hold-tap";
            #binding-cells = <2>;
            tapping-term-ms = <200>;
            bindings = <&EmojiPicker_A>, <&InputSwitch_ALW>;
            flavor = "tap-preferred";
        };

        HT_InputSwitch_EmojiPicker_LW: HT_InputSwitch_EmojiPicker_LW {
            compatible = "zmk,behavior-hold-tap";
            #binding-cells = <2>;
            tapping-term-ms = <200>;
            bindings = <&EmojiPicker_LW>, <&InputSwitch_ALW>;
            flavor = "tap-preferred";
        };

        HT_LayerToggleHold: HT_LayerToggleHold {
            compatible = "zmk,behavior-hold-tap";
            #binding-cells = <2>;
            tapping-term-ms = <200>;
            bindings = <&mo>, <&tog>;
            flavor = "balanced";
        };

        HT_LayerToTo: HT_LayerToTo {
            compatible = "zmk,behavior-hold-tap";
            #binding-cells = <2>;
            tapping-term-ms = <200>;
            bindings = <&to>, <&to>;
            flavor = "balanced";
        };

        HT_MoveSelectBlockNext_A: HT_MoveSelectBlockNext_A {
            compatible = "zmk,behavior-hold-tap";
            #binding-cells = <2>;
            tapping-term-ms = <200>;
            bindings = <&SelectBlockNext_A>, <&MoveBlockNext_A>;
            flavor = "tap-preferred";
        };

        HT_MoveSelectBlockNext_LW: HT_MoveSelectBlockNext_LW {
            compatible = "zmk,behavior-hold-tap";
            #binding-cells = <2>;
            tapping-term-ms = <200>;
            bindings = <&SelectBlockNext_LW>, <&MoveBlockNext_LW>;
            flavor = "tap-preferred";
        };

        HT_MoveSelectBlockPrev_A: HT_MoveSelectBlockPrev_A {
            compatible = "zmk,behavior-hold-tap";
            #binding-cells = <2>;
            tapping-term-ms = <200>;
            bindings = <&SelectBlockPrev_A>, <&MoveBlockPrev_A>;
            flavor = "tap-preferred";
        };

        HT_MoveSelectBlockPrev_LW: HT_MoveSelectBlockPrev_LW {
            compatible = "zmk,behavior-hold-tap";
            #binding-cells = <2>;
            tapping-term-ms = <200>;
            bindings = <&SelectBlockPrev_LW>, <&MoveBlockPrev_LW>;
            flavor = "tap-preferred";
        };









        HT_MoveSelectWordNext_A: HT_MoveSelectWordNext_A {
            compatible = "zmk,behavior-hold-tap";
            #binding-cells = <2>;
            tapping-term-ms = <200>;
            bindings = <&SelectWordNext_A>, <&MoveWordNext_A>;
            flavor = "tap-preferred";
        };

        HT_MoveSelectWordNext_LW: HT_MoveSelectWordNext_LW {
            compatible = "zmk,behavior-hold-tap";
            #binding-cells = <2>;
            tapping-term-ms = <200>;
            bindings = <&SelectWordNext_LW>, <&MoveWordNext_LW>;
            flavor = "tap-preferred";
        };

        HT_MoveSelectWordPrev_A: HT_MoveSelectWordPrev_A {
            compatible = "zmk,behavior-hold-tap";
            #binding-cells = <2>;
            tapping-term-ms = <200>;
            bindings = <&SelectWordPrev_A>, <&MoveWordPrev_A>;
            flavor = "tap-preferred";
        };

        HT_MoveSelectWordPrev_LW: HT_MoveSelectWordPrev_LW {
            compatible = "zmk,behavior-hold-tap";
            #binding-cells = <2>;
            tapping-term-ms = <200>;
            bindings = <&SelectWordPrev_LW>, <&MoveWordPrev_LW>;
            flavor = "tap-preferred";
        };

        HT_Paste_PastePlain_A: HT_Paste_PastePlain_A {
            compatible = "zmk,behavior-hold-tap";
            #binding-cells = <2>;
            tapping-term-ms = <200>;
            bindings = <&PastePlain_A>, <&Paste_A>;
            flavor = "tap-preferred";
        };

        HT_Paste_PastePlain_LW: HT_Paste_PastePlain_LW {
            compatible = "zmk,behavior-hold-tap";
            #binding-cells = <2>;
            tapping-term-ms = <200>;
            bindings = <&PastePlain_LW>, <&Paste_LW>;
            flavor = "tap-preferred";
        };

        HT_Reset_Bootloader: HT_Reset_Bootloader {
            compatible = "zmk,behavior-hold-tap";
            #binding-cells = <2>;
            tapping-term-ms = <200>;
            bindings = <&bootloader>, <&sys_reset>;
            flavor = "tap-preferred";
        };

        // space_layer_access - TailorKey
        HT_Space_Layer: HT_Space_Layer {
            compatible = "zmk,behavior-hold-tap";
            #binding-cells = <2>;
            tapping-term-ms = <200>;
            bindings = <&mo>, <&kp>;
            flavor = "balanced";
            quick-tap-ms = <150>;
        };

        // Sticky-Mod
        HT_StickyMod: HT_StickyMod {
            compatible = "zmk,behavior-hold-tap";
            #binding-cells = <2>;
            tapping-term-ms = <200>;
            bindings = <&kp>, <&sk>;
            flavor = "balanced";
        };

        // thumb_layer_access - TailorKey
        HT_Thumb_Layer: HT_Thumb_Layer {
            compatible = "zmk,behavior-hold-tap";
            #binding-cells = <2>;
            tapping-term-ms = <200>;
            bindings = <&mo>, <&kp>;
            flavor = "balanced";
            quick-tap-ms = <300>;
        };

        HT_Undo_Redo_A: HT_Undo_Redo_A {
            compatible = "zmk,behavior-hold-tap";
            #binding-cells = <2>;
            tapping-term-ms = <200>;
            bindings = <&Redo_A>, <&Undo_A>;
            flavor = "tap-preferred";
        };

        HT_Undo_Redo_LW: HT_Undo_Redo_LW {
            compatible = "zmk,behavior-hold-tap";
            #binding-cells = <2>;
            tapping-term-ms = <200>;
            bindings = <&Redo_LW>, <&Undo_LW>;
            flavor = "tap-preferred";
        };

        HT_WindowRestore_Maximize_A: HT_WindowRestore_Maximize_A {
            compatible = "zmk,behavior-hold-tap";
            #binding-cells = <2>;
            tapping-term-ms = <200>;
            bindings = <&WindowMaximize_A>, <&WindowRestore_A>;
            flavor = "tap-preferred";
        };

        HT_WindowRestore_Maximize_LW: HT_WindowRestore_Maximize_LW {
            compatible = "zmk,behavior-hold-tap";
            #binding-cells = <2>;
            tapping-term-ms = <200>;
            bindings = <&WindowMaximize_LW>, <&WindowRestore_LW>;
            flavor = "tap-preferred";
        };
    };
};




/ {
    macros {
        BLE_Profile_0: BLE_Profile_0 {
            compatible = "zmk,behavior-macro";
            #binding-cells = <0>;
            bindings = <&out OUT_BLE>, <&bt BT_SEL 0>;
        };

        BLE_Profile_1: BLE_Profile_1 {
            compatible = "zmk,behavior-macro";
            #binding-cells = <0>;
            bindings = <&out OUT_BLE>, <&bt BT_SEL 1>;
        };

        BLE_Profile_2: BLE_Profile_2 {
            compatible = "zmk,behavior-macro";
            #binding-cells = <0>;
            bindings = <&out OUT_BLE>, <&bt BT_SEL 2>;
        };

        BLE_Profile_3: BLE_Profile_3 {
            compatible = "zmk,behavior-macro";
            #binding-cells = <0>;
            bindings = <&out OUT_BLE>, <&bt BT_SEL 3>;
        };

        BLE_Profile_4: BLE_Profile_4 {
            compatible = "zmk,behavior-macro";
            #binding-cells = <0>;
            bindings = <&out OUT_BLE>, <&bt BT_SEL 4>;
        };


        MoveLinePrev_ALW: MoveLinePrev_ALW {
            compatible = "zmk,behavior-macro";
            #binding-cells = <0>;
            bindings = <&kp UP>;
        };

        MoveLineNext_ALW: MoveLineNext_ALW {
            compatible = "zmk,behavior-macro";
            #binding-cells = <0>;
            bindings = <&kp DOWN>;
        };

        HT_MoveSelectLinePrev_A: HT_MoveSelectLinePrev_A {
            compatible = "zmk,behavior-hold-tap";
            #binding-cells = <2>;
            tapping-term-ms = <200>;
            bindings = <&SelectLinePrev_A>, <&MoveLinePrev_ALW>;
            flavor = "tap-preferred";
        };

        HT_MoveSelectLineNext_A: HT_MoveSelectLineNext_A {
            compatible = "zmk,behavior-hold-tap";
            #binding-cells = <2>;
            tapping-term-ms = <200>;
            bindings = <&SelectLineNext_A>, <&MoveLineNext_ALW>;
            flavor = "tap-preferred";
        };

        HT_MoveSelectLinePrev_LW: HT_MoveSelectLinePrev_LW {
            compatible = "zmk,behavior-hold-tap";
            #binding-cells = <2>;
            tapping-term-ms = <200>;
            bindings = <&SelectLinePrev_LW>, <&MoveLinePrev_ALW>;
            flavor = "tap-preferred";
        };

        HT_MoveSelectLineNext_LW: HT_MoveSelectLineNext_LW {
            compatible = "zmk,behavior-hold-tap";
            #binding-cells = <2>;
            tapping-term-ms = <200>;
            bindings = <&SelectLineNext_LW>, <&MoveLineNext_ALW>;
            flavor = "tap-preferred";
        };

        PointerLayer_A: PointerLayer_A {
            compatible = "zmk,behavior-tap-dance";
            #binding-cells = <0>;
            tapping-term-ms = <200>;
            bindings = <&mo 15>, <&tog 15>;
        };

        PointerLayer_LW: PointerLayer_LW {
            compatible = "zmk,behavior-tap-dance";
            #binding-cells = <0>;
            tapping-term-ms = <200>;
            bindings = <&mo 16>, <&tog 16>;
        };

        HT_Keypress_LayerMomentary: HT_Keypress_LayerMomentary {
            compatible = "zmk,behavior-hold-tap";
            #binding-cells = <2>;
            tapping-term-ms = <200>;
            bindings = <&mo>, <&kp>;
            flavor = "tap-preferred";
        };

    };
};

/ {
    combos {
        compatible = "zmk,combos";

        combo_ArrowDown {
            key-positions = <20 32>;
            bindings = <&kp DOWN>;
        };

        combo_ArrowLeft {
            key-positions = <18 30>;
            bindings = <&kp LEFT>;
        };

        combo_ArrowRight {
            key-positions = <21 33>;
            bindings = <&kp RIGHT>;
        };

        combo_ArrowUp {
            key-positions = <19 31>;
            bindings = <&kp UP>;
        };

        combo_BT_ClearAll {
            key-positions = <32 33>;
            bindings = <&bt BT_CLR_ALL>;
            layers = <12>;
        };

        combo_BT_ClearBond {
            key-positions = <31 32>;
            bindings = <&bt BT_CLR>;
            layers = <12>;
        };

        combo_FnF01 {
            key-positions = <4 14>;
            bindings = <&kp F1>;
            layers = <13 14>;
        };

        combo_FnF02 {
            key-positions = <3 13>;
            bindings = <&kp F2>;
            layers = <13 14>;
        };

        combo_FnF03 {
            key-positions = <2 12>;
            bindings = <&kp F3>;
            layers = <13 14>;
        };

        combo_FnF04 {
            key-positions = <1 11>;
            bindings = <&kp F4>;
            layers = <13 14>;
        };

        combo_FnF05 {
            key-positions = <0 10>;
            bindings = <&kp F5>;
            layers = <13 14>;
        };

        combo_FnF06 {
            key-positions = <5 17>;
            bindings = <&kp F6>;
            layers = <13 14>;
        };

        combo_FnF07 {
            key-positions = <6 18>;
            bindings = <&kp F7>;
            layers = <13 14>;
        };

        combo_FnF08 {
            key-positions = <7 19>;
            bindings = <&kp F8>;
            layers = <13 14>;
        };

        combo_FnF09 {
            key-positions = <8 20>;
            bindings = <&kp F9>;
            layers = <13 14>;
        };

        combo_FnF10 {
            key-positions = <9 21>;
            bindings = <&kp F10>;
            layers = <13 14>;
        };

        combo_FnF11 {
            key-positions = <14 26>;
            bindings = <&kp F11>;
            layers = <13 14>;
        };

        combo_FnF12 {
            key-positions = <17 29>;
            bindings = <&kp F12>;
            layers = <13 14>;
        };

        combo_MouseWarp_LH {
            key-positions = <14 26>;
            bindings = <&mo 19>;
            layers = <15 16>;
        };

        combo_MouseWarp_RH {
            key-positions = <17 29>;
            bindings = <&mo 19>;
            layers = <15 16>;
        };

        combo_Mute {
            key-positions = <12 13>;
            bindings = <&kp C_MUTE>;
            layers = <12>;
        };

        combo_PlayPause {
            key-positions = <24 25>;
            bindings = <&kp C_PP>;
            layers = <12>;
        };

        combo_SM_LALT_LH_ALW {
            key-positions = <11 23>;
            bindings = <&HT_StickyMod LALT LALT>;
            layers = <0 1 2 3 4 5 6 7 10 11 15 13 14 20 21 16>;
        };

        combo_SM_LCTRL_LH_A {
            key-positions = <10 22>;
            bindings = <&HT_StickyMod LCTRL LCTRL>;
            layers = <0 1 4 5 13 20>;
        };

        combo_SM_LCTRL_LH_LW {
            key-positions = <12 24>;
            bindings = <&HT_StickyMod LCTRL LCTRL>;
            layers = <2 3 6 7 16 14 21>;
        };

        combo_SM_LGUI_LH_A {
            key-positions = <12 24>;
            bindings = <&HT_StickyMod LGUI LGUI>;
            layers = <0 1 4 5 13 20 15>;
        };

        combo_SM_LGUI_LH_LW {
            key-positions = <10 22>;
            bindings = <&HT_StickyMod LGUI LGUI>;
            layers = <2 3 6 7 16 14 21>;
        };

        combo_SM_LSHFT_LH_ALW {
            key-positions = <13 25>;
            bindings = <&HT_StickyMod LSHFT LSHFT>;
            layers = <0 1 2 3 4 5 6 7 10 11 15 13 14 20 21 16>;
        };

        combo_SM_RALT_LH_ALW {
            key-positions = <14 26>;
            bindings = <&HT_StickyMod RALT RALT>;
            layers = <0 1 2 3 4 5 6 7>;
        };

        combo_ToggleLayer_Autoshift_ColemakDH {
            key-positions = <10 34>;
            bindings = <&tog 22>;
            layers = <0 1 3 2>;
        };

        combo_ToggleLayer_Autoshift_Qwerty {
            key-positions = <10 34>;
            bindings = <&tog 23>;
            layers = <4 5 6 7>;
        };

        combo_ToggleLayer_Typing_ColemakDH {
            key-positions = <13 34>;
            bindings = <&tog 25>;
            layers = <0 1 2 3>;
        };

        combo_ToggleLayer_Typing_Qwerty {
            key-positions = <4 34>;
            bindings = <&tog 25>;
            layers = <4 5 6 7>;
        };

        combo_USB_Output {
            key-positions = <30 31>;
            bindings = <&out OUT_USB>;
            layers = <12>;
        };

        combo_ZoomReset_A {
            key-positions = <2 3>;
            bindings = <&ZoomReset_A>;
            layers = <8>;
        };

        combo_ZoomReset_LW {
            key-positions = <2 3>;
            bindings = <&ZoomReset_A>;
            layers = <9>;
        };

        combo_IME_Off_A {
            key-positions = <2 3>;
            bindings = <&IME_Off_A>;
            layers = <0 1 4 5 13 20>;
        };

        combo_IME_Off_LW {
            key-positions = <2 3>;
            bindings = <&IME_Off_LW>;
            layers = <2 3 6 7 14 21>;
        };

        combo_IME_ON_A {
            key-positions = <6 7>;
            bindings = <&IME_ON_A>;
            layers = <0 1 4 5 13 20>;
        };

        combo_InputSwitch_EmojiPicker_A {
            key-positions = <4 5>;
            bindings = <&HT_InputSwitch_EmojiPicker_A 0 0>;
            layers = <0 1 4 5>;
        };

        combo_InputSwitch_EmojiPicker_LW {
            key-positions = <4 5>;
            bindings = <&HT_InputSwitch_EmojiPicker_LW 0 0>;
            layers = <2 3 6 7>;
        };

        combo_ToggleLayer_Mouse_A {
            key-positions = <37 38>;
            bindings = <&tog 15>;
            layers = <0 1 4 8 10 15 5>;
        };

        combo_MomentaryLayer_Magic {
            key-positions = <39 37>;
            bindings = <&mo 12>;
        };

        combo_ShiftEnter {
            key-positions = <33 32>;
            bindings = <&kp LS(RET)>;
            layers = <0 1 2 3 4 5 6 7>;
        };

        combo_Escape {
            key-positions = <38 39>;
            bindings = <&kp ESC>;
        };

        combo_ShiftTab {
            key-positions = <0 1>;
            bindings = <&kp LS(TAB)>;
        };

        combo_CapsWord_Shift {
            key-positions = <40 41>;
            bindings = <&HT_CapsWord_Shift LSHFT 0>;
            layers = <0 1 2 3 4 5 6 7>;
        };

        combo_Tab {
            key-positions = <8 9>;
            bindings = <&kp TAB>;
        };

        combo_IME_ON_LW {
            key-positions = <6 7>;
            bindings = <&IME_ON_LW>;
            layers = <2 3 6 7 14 21>;
        };

        combo_ToggleLayer_Mouse_LW {
            key-positions = <37 38>;
            bindings = <&tog 16>;
            layers = <2 3 6 7 9 11 16>;
        };

    };
};

/ {
    keymap {
        compatible = "zmk,keymap";

        layer_Base_CAE {
            bindings = <
  &kp Q  &kp W  &kp F  &kp P  &kp B  &kp J
  &kp L  &kp U  &kp Y  &kp MINUS  &HRM_LHC5R3 LCTRL A  &HRM_LHC4R3 LALT R
  &HRM_LHC3R3 LGUI S  &HRM_LHC2R3 LSHFT T  &HRM_LHC1R3 RALT G  &none  &mo 26  &HRM_RHC1R3 RALT M
  &HRM_RHC2R3 LSHFT N  &HRM_RHC3R3 LGUI E  &HRM_RHC4R3 LALT I  &HRM_RHC5R3 LCTRL O  &kp Z  &kp X
  &kp C  &HRM_LHC2R4 RCTRL D  &kp V  &none  &none  &kp K
  &HRM_RHC2R4 RCTRL H  &kp COMMA  &kp DOT  &kp SQT  &none  &none
  &none  &PointerLayer_A  &HT_Thumb_Layer 10 BSPC  &HT_Thumb_Layer 8 DEL  &HT_Thumb_Layer 20 RET  &HT_Space_Layer 13 SPACE
  &none
>;
            sensor-bindings = <&inc_dec_kp PG_UP PAGE_DOWN>;
        };

        layer_Base_CAJ {
            bindings = <
  &kp Q  &kp W  &kp F  &kp P  &kp B  &kp J
  &kp L  &kp U  &kp Y  &kp MINUS  &HRM_LHC5R3 LCTRL A  &HRM_LHC4R3 LALT R
  &HRM_LHC3R3 LGUI S  &HRM_LHC2R3 LSHFT T  &HRM_LHC1R3 RALT G  &none  &mo 26  &HRM_RHC1R3 RALT M
  &HRM_RHC2R3 LSHFT N  &HRM_RHC3R3 LGUI E  &HRM_RHC4R3 LALT I  &HRM_RHC5R3 LCTRL O  &kp Z  &kp X
  &kp C  &HRM_LHC2R4 RCTRL D  &kp V  &none  &none  &kp K
  &HRM_RHC2R4 RCTRL H  &kp COMMA  &kp DOT  &kp LS(N7)  &none  &none
  &none  &PointerLayer_A  &HT_Thumb_Layer 10 BSPC  &HT_Thumb_Layer 8 DEL  &HT_Thumb_Layer 21 RET  &HT_Space_Layer 14 SPACE
  &none
>;
            sensor-bindings = <&inc_dec_kp PG_UP PAGE_DOWN>;
        };

        layer_Base_CLWE {
            bindings = <
  &kp Q  &kp W  &kp F  &kp P  &kp B  &kp J
  &kp L  &kp U  &kp Y  &kp MINUS  &HRM_LHC5R3 LGUI A  &HRM_LHC4R3 LALT R
  &HRM_LHC3R3 LCTRL S  &HRM_LHC2R3 LSHFT T  &HRM_LHC1R3 RALT G  &none  &mo 26  &HRM_RHC1R3 RALT M
  &HRM_RHC2R3 LSHFT N  &HRM_RHC3R3 LCTRL E  &HRM_RHC4R3 LALT I  &HRM_RHC5R3 LGUI O  &kp Z  &kp X
  &kp C  &kp D  &kp V  &none  &none  &kp K
  &kp H  &kp COMMA  &kp DOT  &kp SQT  &none  &none
  &none  &PointerLayer_LW  &HT_Thumb_Layer 11 BSPC  &HT_Thumb_Layer 9 DEL  &HT_Thumb_Layer 20 RET  &HT_Space_Layer 13 SPACE
  &none
>;
            sensor-bindings = <&inc_dec_kp PG_UP PAGE_DOWN>;
        };

        layer_Base_CLWJ {
            bindings = <
  &kp Q  &kp W  &kp F  &kp P  &kp B  &kp J
  &kp L  &kp U  &kp Y  &kp MINUS  &HRM_LHC5R3 LGUI A  &HRM_LHC4R3 LALT R
  &HRM_LHC3R3 LCTRL S  &HRM_LHC2R3 LSHFT T  &HRM_LHC1R3 RALT G  &none  &mo 26  &HRM_RHC1R3 RALT M
  &HRM_RHC2R3 LSHFT N  &HRM_RHC3R3 LCTRL E  &HRM_RHC4R3 LALT I  &HRM_RHC5R3 LGUI O  &kp Z  &kp X
  &kp C  &kp D  &kp V  &none  &none  &kp K
  &kp H  &kp COMMA  &kp DOT  &kp LS(N7)  &none  &none
  &none  &PointerLayer_LW  &HT_Thumb_Layer 11 BSPC  &HT_Thumb_Layer 9 DEL  &HT_Thumb_Layer 21 RET  &HT_Space_Layer 14 SPACE
  &none
>;
            sensor-bindings = <&inc_dec_kp PG_UP PAGE_DOWN>;
        };

        layer_Base_QAE {
            bindings = <
  &kp Q  &kp W  &kp E  &kp R  &kp T  &kp Y
  &kp U  &kp I  &kp O  &kp P  &HRM_LHC5R3 LCTRL A  &HRM_LHC4R3 LALT S
  &HRM_LHC3R3 LGUI D  &HRM_LHC2R3 LSHFT F  &HRM_LHC1R3 RALT G  &none  &mo 26  &HRM_RHC1R3 RALT H
  &HRM_RHC2R3 LSHFT J  &HRM_RHC3R3 LGUI K  &HRM_RHC4R3 LALT L  &HRM_RHC5R3 LCTRL MINUS  &kp Z  &kp X
  &kp C  &HRM_LHC2R4 RCTRL V  &kp B  &none  &none  &kp N
  &HRM_RHC2R4 RCTRL M  &kp COMMA  &kp DOT  &kp SQT  &none  &none
  &none  &PointerLayer_A  &HT_Thumb_Layer 10 BSPC  &HT_Thumb_Layer 8 DEL  &HT_Thumb_Layer 20 RET  &HT_Space_Layer 13 SPACE
  &none
>;
            sensor-bindings = <&inc_dec_kp PG_UP PAGE_DOWN>;
        };

        layer_Base_QAJ {
            bindings = <
  &kp Q  &kp W  &kp E  &kp R  &kp T  &kp Y
  &kp U  &kp I  &kp O  &kp P  &HRM_LHC5R3 LCTRL A  &HRM_LHC4R3 LALT S
  &HRM_LHC3R3 LGUI D  &HRM_LHC2R3 LSHFT F  &HRM_LHC1R3 RALT G  &none  &mo 26  &HRM_RHC1R3 RALT H
  &HRM_RHC2R3 LSHFT J  &HRM_RHC3R3 LGUI K  &HRM_RHC4R3 LALT L  &HRM_RHC5R3 LCTRL MINUS  &kp Z  &kp X
  &kp C  &HRM_LHC2R4 RCTRL V  &kp B  &none  &none  &kp N
  &HRM_RHC2R4 RCTRL M  &kp COMMA  &kp DOT  &kp LS(N7)  &none  &none
  &none  &PointerLayer_A  &HT_Thumb_Layer 10 BSPC  &HT_Thumb_Layer 8 DEL  &HT_Thumb_Layer 21 RET  &HT_Space_Layer 14 SPACE
  &none
>;
            sensor-bindings = <&inc_dec_kp PG_UP PAGE_DOWN>;
        };

        layer_Base_QLWE {
            bindings = <
  &kp Q  &kp W  &kp E  &kp R  &kp T  &kp Y
  &kp U  &kp I  &kp O  &kp P  &HRM_LHC5R3 LGUI A  &HRM_LHC4R3 LALT S
  &HRM_LHC3R3 LCTRL D  &HRM_LHC2R3 LSHFT F  &HRM_LHC1R3 RALT G  &none  &mo 26  &HRM_RHC1R3 RALT H
  &HRM_RHC2R3 LSHFT J  &HRM_RHC3R3 LCTRL K  &HRM_RHC4R3 LALT L  &HRM_RHC5R3 LGUI MINUS  &kp Z  &kp X
  &kp C  &kp V  &kp B  &none  &none  &kp N
  &kp M  &kp COMMA  &kp DOT  &kp SQT  &none  &none
  &none  &PointerLayer_LW  &HT_Thumb_Layer 11 BSPC  &HT_Thumb_Layer 9 DEL  &HT_Thumb_Layer 20 RET  &HT_Space_Layer 13 SPACE
  &none
>;
            sensor-bindings = <&inc_dec_kp PG_UP PAGE_DOWN>;
        };

        layer_Base_QLWJ {
            bindings = <
  &kp Q  &kp W  &kp E  &kp R  &kp T  &kp Y
  &kp U  &kp I  &kp O  &kp P  &HRM_LHC5R3 LGUI A  &HRM_LHC4R3 LALT S
  &HRM_LHC3R3 LCTRL D  &HRM_LHC2R3 LSHFT F  &HRM_LHC1R3 RALT G  &none  &mo 26  &HRM_RHC1R3 RALT H
  &HRM_RHC2R3 LSHFT J  &HRM_RHC3R3 LCTRL K  &HRM_RHC4R3 LALT L  &HRM_RHC5R3 LGUI MINUS  &kp Z  &kp X
  &kp C  &kp V  &kp B  &none  &none  &kp N
  &kp M  &kp COMMA  &kp DOT  &kp LS(N7)  &none  &none
  &none  &PointerLayer_LW  &HT_Thumb_Layer 11 BSPC  &HT_Thumb_Layer 9 DEL  &HT_Thumb_Layer 21 RET  &HT_Space_Layer 14 SPACE
  &none
>;
            sensor-bindings = <&inc_dec_kp PG_UP PAGE_DOWN>;
        };

        layer_CursorNav_A {
            bindings = <
  &none  &none  &ZoomOut_A  &ZoomIn_A  &none  &WindowClose_A
  &HT_WindowRestore_Maximize_A 0 0  &AppPrev_A  &AppNext_A  &FullscreenToggle_A  &TabPrev_ALW  &HistoryBack_A
  &HistoryForward_A  &TabNext_ALW  &none  &none  &mo 26  &ScreenCapture_A
  &DesktopLeft_A  &TaskView_A  &SystemSearch_A  &DesktopRight_A  &ScreenLock_A  &DevTools_A
  &CommandPalette_A  &URLbar_A  &HT_Copilot_A 0 0  &none  &none  &none
  &SnapLeft_A  &SnapUp_A  &SnapDown_A  &SnapRight_A  &none  &none
  &none  &tog 8  &trans  &trans  &trans  &trans
  &none
>;
            sensor-bindings = <&inc_dec_kp PG_UP PAGE_DOWN>;
        };

        layer_CursorNav_LW {
            bindings = <
  &none  &none  &ZoomOut_LW  &ZoomIn_LW  &none  &WindowClose_LW
  &HT_WindowRestore_Maximize_LW 0 0  &AppPrev_LW  &AppNext_LW  &FullscreenToggle_LW  &TabPrev_ALW  &HistoryBack_LW
  &HistoryForward_LW  &TabNext_ALW  &none  &none  &mo 26  &ScreenCapture_LW
  &DesktopLeft_LW  &TaskView_LW  &SystemSearch_LW  &DesktopRight_LW  &ScreenLock_LW  &DevTools_LW
  &CommandPalette_LW  &URLbar_LW  &HT_Copilot_LW 0 0  &none  &none  &none
  &SnapLeft_LW  &SnapUp_LW  &SnapDown_LW  &SnapRight_LW  &none  &none
  &none  &tog 9  &trans  &trans  &trans  &trans
  &none
>;
            sensor-bindings = <&inc_dec_kp PG_UP PAGE_DOWN>;
        };

        layer_CursorText_A {
            bindings = <
  &none  &FindPrev_A  &HT_Find_Replace_A 0 0  &FindNext_A  &HT_CaseCycle_Reconvert_A 0 0  &none
  &HT_MoveSelectWordPrev_A 0 0  &HT_MoveSelectBlockPrev_A 0 0  &HT_MoveSelectBlockNext_A 0 0  &HT_MoveSelectWordNext_A 0 0  &SelectAll_A  &SelectWholeBlock_A
  &SelectWholeLine_A  &SelectWholeWord_A  &SelectClear_ALW  &none  &mo 26  &none
  &mt LS(LEFT) LEFT  &HT_MoveSelectLinePrev_A 0 0  &HT_MoveSelectLineNext_A 0 0  &mt LS(RIGHT) RIGHT  &HT_Undo_Redo_A 0 0  &Cut_A
  &Copy_A  &HT_Paste_PastePlain_A 0 0  &ClipboardHistory_A  &none  &none  &none
  &kp HOME  &kp PG_UP  &kp PG_DN  &kp END  &none  &none
  &none  &tog 10  &trans  &trans  &trans  &trans
  &none
>;
            sensor-bindings = <&inc_dec_kp PG_UP PAGE_DOWN>;
        };

        layer_CursorText_LW {
            bindings = <
  &none  &FindPrev_LW  &HT_Find_Replace_LW 0 0  &FindNext_LW  &HT_CaseCycle_Reconvert_LW 0 0  &none
  &HT_MoveSelectWordPrev_LW 0 0  &HT_MoveSelectBlockPrev_LW 0 0  &HT_MoveSelectBlockNext_LW 0 0  &HT_MoveSelectWordNext_LW 0 0  &SelectAll_LW  &SelectWholeBlock_LW
  &SelectWholeLine_LW  &SelectWholeWord_LW  &SelectClear_ALW  &none  &mo 26  &none
  &mt LS(LEFT) LEFT  &HT_MoveSelectLinePrev_LW 0 0  &HT_MoveSelectLineNext_LW 0 0  &mt LS(RIGHT) RIGHT  &HT_Undo_Redo_LW 0 0  &Cut_LW
  &Copy_LW  &HT_Paste_PastePlain_LW 0 0  &ClipboardHistory_LW  &none  &none  &none
  &kp HOME  &kp PG_UP  &kp PG_DN  &kp END  &none  &none
  &none  &tog 11  &trans  &trans  &trans  &trans
  &none
>;
            sensor-bindings = <&inc_dec_kp PG_UP PAGE_DOWN>;
        };

        layer_Magic {
            bindings = <
  &none  &none  &kp C_BRI_DN  &kp C_BRI_UP  &HT_Reset_Bootloader 0 0  &HT_Reset_Bootloader 0 0
  &to 4  &to 5  &to 6  &to 7  &none  &none
  &kp C_VOL_DN  &kp C_VOL_UP  &rgb_ug RGB_TOG  &none  &mo 26  &rgb_ug RGB_TOG
  &to 0  &to 1  &to 2  &to 3  &none  &none
  &kp C_PREV  &kp C_NEXT  &none  &none  &none  &BLE_Profile_0
  &BLE_Profile_1  &BLE_Profile_2  &BLE_Profile_3  &BLE_Profile_4  &none  &none
  &none  &tog 12  &none  &none  &none  &none
  &none
>;
            sensor-bindings = <&inc_dec_kp PG_UP PAGE_DOWN>;
        };

        layer_Number_E {
            bindings = <
  &none  &kp LS(N9)  &kp LS(N0)  &none  &kp LS(SEMI)  &kp LS(N8)
  &kp LS(EQUAL)  &kp EQUAL  &kp LS(N5)  &kp MINUS  &HRM_LHC5R3 LCTRL N5  &HRM_LHC4R3 LALT N4
  &HRM_LHC3R3 LGUI N3  &HRM_LHC2R3 LSHFT N2  &kp N1  &none  &mo 26  &kp N6
  &HRM_RHC2R3 LSHFT N7  &HRM_RHC3R3 LGUI N8  &HRM_RHC4R3 LALT N9  &HRM_RHC5R3 LCTRL N0  &none  &kp LS(COMMA)
  &kp LS(DOT)  &none  &kp FSLH  &none  &none  &none
  &none  &kp COMMA  &kp DOT  &kp SQT  &none  &none
  &none  &tog 13  &trans  &trans  &trans  &trans
  &none
>;
            sensor-bindings = <&inc_dec_kp PG_UP PAGE_DOWN>;
        };

        layer_Number_J {
            bindings = <
  &none  &kp LS(N8)  &kp LS(N9)  &none  &kp LS(N7)  &kp LS(SQT)
  &kp LS(SEMI)  &kp LS(MINUS)  &kp LS(N5)  &kp MINUS  &HRM_LHC5R3 LGUI N5  &HRM_LHC4R3 LALT N4
  &HRM_LHC3R3 LCTRL N3  &HRM_LHC2R3 LSHFT N2  &kp N1  &none  &mo 26  &kp N6
  &HRM_RHC2R3 LSHFT N7  &HRM_RHC3R3 LCTRL N8  &HRM_RHC4R3 LALT N9  &HRM_RHC5R3 LGUI N0  &none  &kp LS(COMMA)
  &kp LS(DOT)  &none  &kp FSLH  &none  &none  &none
  &none  &kp COMMA  &kp DOT  &kp LS(N7)  &none  &none
  &none  &tog 14  &trans  &trans  &trans  &trans
  &none
>;
            sensor-bindings = <&inc_dec_kp PG_UP PAGE_DOWN>;
        };

        layer_Pointer_Default_A {
            bindings = <
  &mkp MB5  &mkp RCLK  &mkp MCLK  &mkp LCLK  &mkp MB4  &mkp MB4
  &mkp LCLK  &mkp MCLK  &mkp RCLK  &mkp MB5  &SelectAll_A  &SelectWholeBlock_A
  &SelectWholeLine_A  &SelectWholeWord_A  &mo 18  &none  &mo 26  &mo 18
  &msc SCRL_LEFT  &msc SCRL_DOWN  &msc SCRL_UP  &msc SCRL_RIGHT  &HT_Undo_Redo_A 0 0  &Cut_A
  &HT_Copy_ClipboardHistory_A 0 0  &HT_Paste_PastePlain_A 0 0  &mo 17  &trans  &trans  &mo 17
  &mmv MOVE_LEFT  &mmv MOVE_UP  &mmv MOVE_DOWN  &mmv MOVE_RIGHT  &none  &none
  &none  &PointerLayer_A  &trans  &trans  &trans  &trans
  &none
>;
            sensor-bindings = <&inc_dec_kp PG_UP PAGE_DOWN>;
        };

        layer_Pointer_Default_LW {
            bindings = <
  &mkp MB5  &mkp RCLK  &mkp MCLK  &mkp LCLK  &mkp MB4  &mkp MB4
  &mkp LCLK  &mkp MCLK  &mkp RCLK  &mkp MB5  &SelectAll_LW  &SelectWholeBlock_LW
  &SelectWholeLine_LW  &SelectWholeWord_LW  &mo 18  &none  &mo 26  &mo 18
  &msc SCRL_LEFT  &msc SCRL_UP  &msc SCRL_DOWN  &msc SCRL_RIGHT  &Undo_LW  &Cut_LW
  &HT_Copy_ClipboardHistory_LW 0 0  &HT_Paste_PastePlain_LW 0 0  &mo 17  &trans  &trans  &mo 17
  &mmv MOVE_LEFT  &mmv MOVE_UP  &mmv MOVE_DOWN  &mmv MOVE_RIGHT  &none  &none
  &none  &PointerLayer_LW  &trans  &trans  &trans  &trans
  &none
>;
            sensor-bindings = <&inc_dec_kp PG_UP PAGE_DOWN>;
        };

        layer_Pointer_Precision {
            bindings = <
  &trans  &trans  &trans  &trans  &trans  &trans
  &trans  &trans  &trans  &trans  &trans  &trans
  &trans  &trans  &trans  &none  &mo 26  &trans
  &trans  &trans  &trans  &trans  &trans  &trans
  &trans  &trans  &trans  &trans  &trans  &trans
  &trans  &trans  &trans  &trans  &trans  &none
  &trans  &trans  &trans  &trans  &trans  &trans
  &trans
>;
            sensor-bindings = <&inc_dec_kp PG_UP PAGE_DOWN>;
        };

        layer_Pointer_Rapid {
            bindings = <
  &trans  &trans  &trans  &trans  &trans  &trans
  &trans  &trans  &trans  &trans  &trans  &trans
  &trans  &trans  &trans  &none  &mo 26  &trans
  &trans  &trans  &trans  &trans  &trans  &trans
  &trans  &trans  &trans  &trans  &trans  &trans
  &trans  &trans  &trans  &trans  &trans  &none
  &trans  &trans  &trans  &trans  &trans  &trans
  &trans
>;
            sensor-bindings = <&inc_dec_kp PG_UP PAGE_DOWN>;
        };

        layer_Pointer_Travel {
            bindings = <
  &trans  &trans  &trans  &trans  &trans  &trans
  &trans  &trans  &trans  &trans  &trans  &trans
  &trans  &trans  &trans  &none  &mo 26  &trans
  &trans  &trans  &trans  &trans  &trans  &trans
  &trans  &trans  &trans  &trans  &trans  &trans
  &trans  &trans  &trans  &trans  &trans  &none
  &trans  &trans  &trans  &trans  &trans  &trans
  &trans
>;
            sensor-bindings = <&inc_dec_kp PG_UP PAGE_DOWN>;
        };

        layer_Symbol_E {
            bindings = <
  &kp LS(LBKT)  &kp LS(N9)  &kp LS(N0)  &kp LS(RBKT)  &kp LS(FSLH)  &kp LS(N1)
  &kp LS(EQUAL)  &kp EQUAL  &kp LS(N5)  &mt LS(GRAVE) MINUS  &HRM_LHC5R3 LCTRL LS(N3)  &HRM_LHC4R3 LALT LS(N6)
  &HRM_LHC3R3 LGUI LS(MINUS)  &HRM_LHC2R3 LSHFT LS(N4)  &kp LS(N8)  &none  &mo 26  &kp LS(N7)
  &HRM_RHC2R3 LSHFT LS(N2)  &HRM_RHC3R3 LGUI SEMI  &HRM_RHC4R3 LALT LS(SEMI)  &HRM_RHC5R3 LCTRL LS(SQT)  &kp LBKT  &kp LS(COMMA)
  &kp LS(DOT)  &kp RBKT  &kp FSLH  &none  &none  &kp BSLH
  &kp LS(BSLH)  &kp COMMA  &kp DOT  &mt GRAVE SQT  &none  &none
  &none  &tog 20  &trans  &trans  &trans  &trans
  &none
>;
            sensor-bindings = <&inc_dec_kp PG_UP PAGE_DOWN>;
        };

        layer_Symbol_J {
            bindings = <
  &kp LS(RBKT)  &kp LS(N8)  &kp LS(N9)  &kp LS(BSLH)  &kp LS(FSLH)  &kp LS(N1)
  &kp LS(SEMI)  &kp LS(MINUS)  &kp LS(N5)  &mt LS(EQUAL) MINUS  &HRM_LHC5R3 LGUI LS(N3)  &HRM_LHC4R3 LALT EQUAL
  &HRM_LHC3R3 LCTRL LS(INT1)  &HRM_LHC2R3 LSHFT LS(N4)  &kp LS(SQT)  &none  &mo 26  &kp LS(N6)
  &HRM_RHC2R3 LSHFT LBKT  &HRM_RHC3R3 LCTRL SEMI  &HRM_RHC4R3 LALT SQT  &HRM_RHC5R3 LGUI LS(N2)  &kp RBKT  &kp LS(COMMA)
  &kp LS(DOT)  &kp BSLH  &kp FSLH  &none  &none  &kp INT1
  &kp LS(INT3)  &kp COMMA  &kp DOT  &mt LS(LBKT) LS(N7)  &none  &none
  &none  &tog 21  &trans  &trans  &trans  &trans
  &none
>;
            sensor-bindings = <&inc_dec_kp PG_UP PAGE_DOWN>;
        };

        layer_TypingAutoshift_C {
            bindings = <
  &AS_v1_TKZ Q  &AS_v1_TKZ W  &AS_v1_TKZ F  &AS_v1_TKZ P  &AS_v1_TKZ B  &AS_v1_TKZ J
  &AS_v1_TKZ L  &AS_v1_TKZ U  &AS_v1_TKZ Y  &trans  &AS_v1_TKZ A  &AS_v1_TKZ R
  &AS_v1_TKZ S  &AS_v1_TKZ T  &AS_v1_TKZ G  &none  &mo 26  &AS_v1_TKZ M
  &AS_v1_TKZ N  &AS_v1_TKZ E  &AS_v1_TKZ I  &AS_v1_TKZ O  &AS_v1_TKZ Z  &AS_v1_TKZ X
  &AS_v1_TKZ C  &AS_v1_TKZ D  &AS_v1_TKZ V  &trans  &trans  &AS_v1_TKZ K
  &AS_v1_TKZ H  &trans  &trans  &trans  &trans  &none
  &trans  &tog 22  &trans  &trans  &trans  &trans
  &trans
>;
            sensor-bindings = <&inc_dec_kp PG_UP PAGE_DOWN>;
        };

        layer_TypingAutoshift_Q {
            bindings = <
  &AS_v1_TKZ Q  &AS_v1_TKZ W  &AS_v1_TKZ E  &AS_v1_TKZ R  &AS_v1_TKZ T  &AS_v1_TKZ Y
  &AS_v1_TKZ U  &AS_v1_TKZ I  &AS_v1_TKZ O  &AS_v1_TKZ P  &AS_v1_TKZ A  &AS_v1_TKZ S
  &AS_v1_TKZ D  &AS_v1_TKZ F  &AS_v1_TKZ G  &none  &mo 26  &AS_v1_TKZ H
  &AS_v1_TKZ J  &AS_v1_TKZ K  &AS_v1_TKZ L  &trans  &AS_v1_TKZ Z  &AS_v1_TKZ X
  &AS_v1_TKZ C  &AS_v1_TKZ V  &AS_v1_TKZ B  &trans  &trans  &AS_v1_TKZ N
  &AS_v1_TKZ M  &trans  &trans  &trans  &trans  &none
  &trans  &tog 23  &trans  &trans  &trans  &trans
  &trans
>;
            sensor-bindings = <&inc_dec_kp PG_UP PAGE_DOWN>;
        };

        layer_TypingFocus_C {
            bindings = <
  &trans  &trans  &trans  &trans  &trans  &trans
  &trans  &trans  &trans  &trans  &kp A  &kp R
  &kp S  &kp T  &kp G  &none  &mo 26  &kp M
  &kp N  &kp E  &kp I  &kp O  &trans  &trans
  &trans  &kp D  &trans  &trans  &trans  &trans
  &kp H  &trans  &trans  &trans  &trans  &none
  &trans  &tog 24  &trans  &trans  &trans  &trans
  &trans
>;
            sensor-bindings = <&inc_dec_kp PG_UP PAGE_DOWN>;
        };

        layer_TypingFocus_Q {
            bindings = <
  &trans  &trans  &trans  &trans  &trans  &trans
  &trans  &trans  &trans  &trans  &kp A  &kp S
  &kp D  &kp F  &kp G  &none  &mo 26  &kp H
  &kp J  &kp K  &kp L  &kp SEMI  &trans  &trans
  &trans  &kp V  &trans  &trans  &trans  &trans
  &kp M  &trans  &trans  &trans  &trans  &none
  &trans  &tog 25  &trans  &trans  &trans  &trans
  &trans
>;
            sensor-bindings = <&inc_dec_kp PG_UP PAGE_DOWN>;
        };

        layer_HSCROLL {
            bindings = <
  &none  &none  &none  &none  &none  &none
  &none  &none  &none  &none  &none  &none
  &none  &none  &none  &none  &none  &none
  &none  &none  &none  &none  &none  &none
  &none  &none  &none  &none  &none  &none
  &none  &none  &none  &none  &none  &none
  &none  &none  &none  &none  &none  &none
  &none
>;
            sensor-bindings = <&inc_dec_kp LEFT RIGHT>;
        };

    };
};
